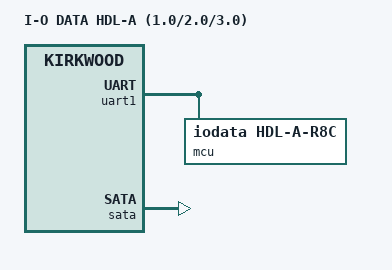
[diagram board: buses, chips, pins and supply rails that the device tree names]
// SPDX-License-Identifier: GPL-2.0-or-later OR MIT

#include "kirkwood-hdlx-a.dtsi"

/ {
	model = "I-O DATA HDL-A (1.0/2.0/3.0)";
	compatible = "iodata,hdl-a", "marvell,kirkwood-88f6282", "marvell,kirkwood";
};

&uart1 {
	status = "okay";

	mcu {
		compatible = "iodata,hdl-a-r8c";

		keys {
			compatible = "iodata,landisk-r8c-keys";
		};

		/* for Status LED */
		leds {
			compatible = "iodata,landisk-r8c-leds";
		};

		hwmon {
			compatible = "iodata,landisk-r8c-hwmon";
		};

		reset {
			compatible = "iodata,landisk-r8c-reset";
		};
	};
};

&sata {
	status = "okay";
	nr-ports = <1>;
};
